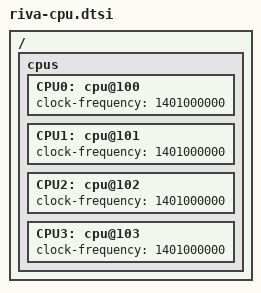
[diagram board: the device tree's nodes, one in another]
/{
	cpus {
  		CPU0: cpu@100 {
    			clock-frequency = <1401000000>;
  		};
  		CPU1: cpu@101 {
    			clock-frequency = <1401000000>;
  		};
  		CPU2: cpu@102 {
    			clock-frequency = <1401000000>;
  		};
  		CPU3: cpu@103 {
    			clock-frequency = <1401000000>;
  		};
	};
};
